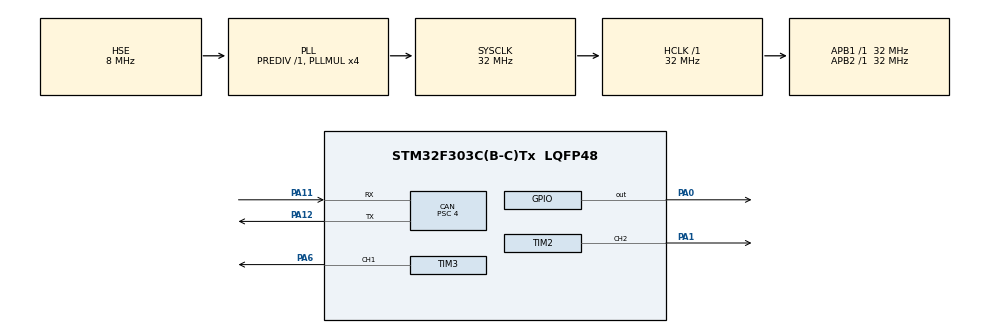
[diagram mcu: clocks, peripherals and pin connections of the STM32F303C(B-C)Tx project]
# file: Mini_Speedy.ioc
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CAN.BS1=CAN_BS1_5TQ
CAN.BS2=CAN_BS2_2TQ
CAN.CalculateBaudRate=1000000
CAN.CalculateTimeBit=1000
CAN.CalculateTimeQuantum=125.0
CAN.Prescaler=4
Mcu.Family=STM32F3
Mcu.Name=STM32F303C(B-C)Tx
Mcu.Package=LQFP48
NVIC.PriorityGroup=NVIC_PRIORITYGROUP_4
PA0.Signal=GPIO_Output
PA1.Signal=S_TIM2_CH2
PA11.Mode=CAN_Activate
PA11.Signal=CAN_RX
PA12.Mode=CAN_Activate
PA12.Signal=CAN_TX
PA6.Signal=S_TIM3_CH1
PF0-OSC_IN.Mode=HSE-External-Oscillator
PF0-OSC_IN.Signal=RCC_OSC_IN
PF1-OSC_OUT.Mode=HSE-External-Oscillator
PF1-OSC_OUT.Signal=RCC_OSC_OUT
ProjectManager.HeapSize=0x200
ProjectManager.StackSize=0x400
ProjectManager.TargetToolchain=STM32CubeIDE
RCC.AHBFreq_Value=32000000
RCC.APB1Freq_Value=32000000
RCC.APB1TimFreq_Value=32000000
RCC.APB2Freq_Value=32000000
RCC.APB2TimFreq_Value=32000000
RCC.CortexFreq_Value=32000000
RCC.HCLKFreq_Value=32000000
RCC.HSE_VALUE=8000000
RCC.HSI_VALUE=8000000
RCC.LSE_VALUE=32768
RCC.PLLMUL=RCC_PLL_MUL4
RCC.PLLSourceVirtual=RCC_PLLSOURCE_HSE
RCC.SYSCLKFreq_VALUE=32000000
RCC.SYSCLKSourceVirtual=RCC_SYSCLKSOURCE_PLLCLK
RCC.USBFreq_Value=32000000
SH.S_TIM2_CH2.0=TIM2_CH2,PWM Generation2 CH2
SH.S_TIM3_CH1.0=TIM3_CH1,PWM Generation1 CH1
TIM2.AutoReloadPreload=TIM_AUTORELOAD_PRELOAD_ENABLE
TIM2.Channel-PWM\ Generation2\ CH2=TIM_CHANNEL_2
TIM2.Period=255
TIM2.Prescaler=6
TIM3.AutoReloadPreload=TIM_AUTORELOAD_PRELOAD_ENABLE
TIM3.Channel-PWM\ Generation1\ CH1=TIM_CHANNEL_1
TIM3.Period=999
TIM3.Prescaler=639
TIM3.Pulse-PWM\ Generation1\ CH1=75
VP_TIM2_VS_ClockSourceINT.Mode=Internal
VP_TIM3_VS_ClockSourceINT.Mode=Internal
board=custom

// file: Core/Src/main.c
/* USER CODE BEGIN Header */
/**
  ******************************************************************************
  * @file           : main.c
  * @brief          : Main program body
  ******************************************************************************
  * @attention
  *
  * Copyright (c) 2024 STMicroelectronics.
  * All rights reserved.
  *
  * This software is licensed under terms that can be found in the LICENSE file
  * in the root directory of this software component.
  * If no LICENSE file comes with this software, it is provided AS-IS.
  *
  ******************************************************************************
  */
/* USER CODE END Header */
#include "main.h"

/* USER CODE BEGIN PD */

// CAN ID of device (4 bits)
#define CAN_ID 0b0001

#define CAN_ID_MASK 		0b00000000000011110000000000000000
#define CAN_ACTUATOR_MASK 	0b00000000000000001111000000000000

// The number of data bytes in the CAN data frames (float32 values).
#define CAN_DATA_SIZE 4

/* USER CODE END PD */

CAN_HandleTypeDef hcan;

TIM_HandleTypeDef htim2;
TIM_HandleTypeDef htim3;

void SystemClock_Config(void);
static void MX_GPIO_Init(void);
static void MX_CAN_Init(void);
static void MX_TIM2_Init(void);
static void MX_TIM3_Init(void);

/* USER CODE BEGIN 0 */
void CAN_Transmit(
    CAN_HandleTypeDef* hcan,
    CAN_TxHeaderTypeDef* CAN_TxHeader,
    uint32_t* CAN_TxMailbox);
// Initializes the CANBus filter for the board.
void CAN_Filter(CAN_HandleTypeDef* hcan, CAN_TxHeaderTypeDef* CAN_TxHeader);

/* USER CODE END 0 */

int main(void)
{

  /* MCU Configuration--------------------------------------------------------*/

  /* Reset of all peripherals, Initializes the Flash interface and the Systick. */
  HAL_Init();

  /* Configure the system clock */
  SystemClock_Config();

  /* Initialize all configured peripherals */
  MX_GPIO_Init();
  MX_CAN_Init();
  MX_TIM2_Init();
  MX_TIM3_Init();
  /* USER CODE BEGIN 2 */
  HAL_TIM_PWM_Start(&htim2, TIM_CHANNEL_2);
  HAL_TIM_PWM_Start(&htim3, TIM_CHANNEL_1);

  CAN_TxHeaderTypeDef CAN_TxHeader; // The transmission header.
  CAN_RxHeaderTypeDef CAN_RxHeader; // The receiver header.
  uint32_t CAN_TxMailbox = 0;
  uint8_t CAN_TxData[CAN_DATA_SIZE] = {};
  uint8_t CAN_RxData[CAN_DATA_SIZE] = {};
  CAN_Filter(&hcan, &CAN_TxHeader); // Initializing the CANbus filter
  HAL_CAN_Start(&hcan);

  int pulse = 0;

  /* USER CODE END 2 */

  /* Infinite loop */
  /* USER CODE BEGIN WHILE */
  while (1)
  {
	  pulse = pulse + 1;
	  if (pulse > 255) {
		  pulse = 0;
	  }
	  //__HAL_TIM_SET_COMPARE(&htim2, TIM_CHANNEL_2, pulse);

	  HAL_Delay(500);

	  if (HAL_CAN_GetRxFifoFillLevel(&hcan, CAN_RX_FIFO0) == 0){
		  continue;
	  }
	  HAL_CAN_GetRxMessage(&hcan, CAN_RX_FIFO0, &CAN_RxHeader, CAN_RxData);
	  uint8_t actuatorID = (uint8_t)((CAN_RxHeader.ExtId & CAN_ACTUATOR_MASK) >> 12);

	  CAN_TxData[0] = (uint8_t)((CAN_RxHeader.ExtId) >> 24);;
	  CAN_TxData[1] = (uint8_t)((CAN_RxHeader.ExtId) >> 16);;
	  CAN_TxData[2] = (uint8_t)((CAN_RxHeader.ExtId) >> 8);;
	  CAN_TxData[3] = (uint8_t)((CAN_RxHeader.ExtId) >> 0);;
	  HAL_CAN_AddTxMessage(&hcan, &CAN_TxHeader, CAN_TxData, &CAN_TxMailbox);

	  switch(actuatorID){
		  case 0b0000:{
			  CAN_TxData[0] = 0b0001;
			  CAN_TxData[1] = 0;
			  CAN_TxData[2] = 0;
			  CAN_TxData[3] = 0;
			  HAL_CAN_AddTxMessage(&hcan, &CAN_TxHeader, CAN_TxData, &CAN_TxMailbox);
		  }
		  case 0b0001:{
			  __HAL_TIM_SET_COMPARE(&htim3, TIM_CHANNEL_1, CAN_RxData[0]);
			  break;
		  }
		  case 0b0010:{
			  break;
		  }
	  }
    /* USER CODE END WHILE */

  }
}

void SystemClock_Config(void)
{
  RCC_OscInitTypeDef RCC_OscInitStruct = {0};
  RCC_ClkInitTypeDef RCC_ClkInitStruct = {0};

  /** Initializes the RCC Oscillators according to the specified parameters
  * in the RCC_OscInitTypeDef structure.
  */
  RCC_OscInitStruct.OscillatorType = RCC_OSCILLATORTYPE_HSE;
  RCC_OscInitStruct.HSEState = RCC_HSE_ON;
  RCC_OscInitStruct.HSEPredivValue = RCC_HSE_PREDIV_DIV1;
  RCC_OscInitStruct.HSIState = RCC_HSI_ON;
  RCC_OscInitStruct.PLL.PLLState = RCC_PLL_ON;
  RCC_OscInitStruct.PLL.PLLSource = RCC_PLLSOURCE_HSE;
  RCC_OscInitStruct.PLL.PLLMUL = RCC_PLL_MUL4;
  if (HAL_RCC_OscConfig(&RCC_OscInitStruct) != HAL_OK)
  {
    Error_Handler();
  }

  /** Initializes the CPU, AHB and APB buses clocks
  */
  RCC_ClkInitStruct.ClockType = RCC_CLOCKTYPE_HCLK|RCC_CLOCKTYPE_SYSCLK
                              |RCC_CLOCKTYPE_PCLK1|RCC_CLOCKTYPE_PCLK2;
  RCC_ClkInitStruct.SYSCLKSource = RCC_SYSCLKSOURCE_PLLCLK;
  RCC_ClkInitStruct.AHBCLKDivider = RCC_SYSCLK_DIV1;
  RCC_ClkInitStruct.APB1CLKDivider = RCC_HCLK_DIV1;
  RCC_ClkInitStruct.APB2CLKDivider = RCC_HCLK_DIV1;

  if (HAL_RCC_ClockConfig(&RCC_ClkInitStruct, FLASH_LATENCY_1) != HAL_OK)
  {
    Error_Handler();
  }
}

static void MX_CAN_Init(void)
{

  hcan.Instance = CAN;
  hcan.Init.Prescaler = 4;
  hcan.Init.Mode = CAN_MODE_NORMAL;
  hcan.Init.SyncJumpWidth = CAN_SJW_1TQ;
  hcan.Init.TimeSeg1 = CAN_BS1_5TQ;
  hcan.Init.TimeSeg2 = CAN_BS2_2TQ;
  hcan.Init.TimeTriggeredMode = DISABLE;
  hcan.Init.AutoBusOff = DISABLE;
  hcan.Init.AutoWakeUp = DISABLE;
  hcan.Init.AutoRetransmission = DISABLE;
  hcan.Init.ReceiveFifoLocked = DISABLE;
  hcan.Init.TransmitFifoPriority = DISABLE;
  if (HAL_CAN_Init(&hcan) != HAL_OK)
  {
    Error_Handler();
  }

}

static void MX_TIM2_Init(void)
{

  TIM_ClockConfigTypeDef sClockSourceConfig = {0};
  TIM_MasterConfigTypeDef sMasterConfig = {0};
  TIM_OC_InitTypeDef sConfigOC = {0};

  htim2.Instance = TIM2;
  htim2.Init.Prescaler = 0;
  htim2.Init.CounterMode = TIM_COUNTERMODE_UP;
  htim2.Init.Period = 255;
  htim2.Init.ClockDivision = TIM_CLOCKDIVISION_DIV1;
  htim2.Init.AutoReloadPreload = TIM_AUTORELOAD_PRELOAD_ENABLE;
  if (HAL_TIM_Base_Init(&htim2) != HAL_OK)
  {
    Error_Handler();
  }
  sClockSourceConfig.ClockSource = TIM_CLOCKSOURCE_INTERNAL;
  if (HAL_TIM_ConfigClockSource(&htim2, &sClockSourceConfig) != HAL_OK)
  {
    Error_Handler();
  }
  if (HAL_TIM_PWM_Init(&htim2) != HAL_OK)
  {
    Error_Handler();
  }
  sMasterConfig.MasterOutputTrigger = TIM_TRGO_RESET;
  sMasterConfig.MasterSlaveMode = TIM_MASTERSLAVEMODE_DISABLE;
  if (HAL_TIMEx_MasterConfigSynchronization(&htim2, &sMasterConfig) != HAL_OK)
  {
    Error_Handler();
  }
  sConfigOC.OCMode = TIM_OCMODE_PWM1;
  sConfigOC.Pulse = 0;
  sConfigOC.OCPolarity = TIM_OCPOLARITY_HIGH;
  sConfigOC.OCFastMode = TIM_OCFAST_DISABLE;
  if (HAL_TIM_PWM_ConfigChannel(&htim2, &sConfigOC, TIM_CHANNEL_2) != HAL_OK)
  {
    Error_Handler();
  }
  HAL_TIM_MspPostInit(&htim2);

}

static void MX_TIM3_Init(void)
{

  TIM_ClockConfigTypeDef sClockSourceConfig = {0};
  TIM_MasterConfigTypeDef sMasterConfig = {0};
  TIM_OC_InitTypeDef sConfigOC = {0};

  htim3.Instance = TIM3;
  htim3.Init.Prescaler = 639;
  htim3.Init.CounterMode = TIM_COUNTERMODE_UP;
  htim3.Init.Period = 999;
  htim3.Init.ClockDivision = TIM_CLOCKDIVISION_DIV1;
  htim3.Init.AutoReloadPreload = TIM_AUTORELOAD_PRELOAD_ENABLE;
  if (HAL_TIM_Base_Init(&htim3) != HAL_OK)
  {
    Error_Handler();
  }
  sClockSourceConfig.ClockSource = TIM_CLOCKSOURCE_INTERNAL;
  if (HAL_TIM_ConfigClockSource(&htim3, &sClockSourceConfig) != HAL_OK)
  {
    Error_Handler();
  }
  if (HAL_TIM_PWM_Init(&htim3) != HAL_OK)
  {
    Error_Handler();
  }
  sMasterConfig.MasterOutputTrigger = TIM_TRGO_RESET;
  sMasterConfig.MasterSlaveMode = TIM_MASTERSLAVEMODE_DISABLE;
  if (HAL_TIMEx_MasterConfigSynchronization(&htim3, &sMasterConfig) != HAL_OK)
  {
    Error_Handler();
  }
  sConfigOC.OCMode = TIM_OCMODE_PWM1;
  sConfigOC.Pulse = 75;
  sConfigOC.OCPolarity = TIM_OCPOLARITY_HIGH;
  sConfigOC.OCFastMode = TIM_OCFAST_DISABLE;
  if (HAL_TIM_PWM_ConfigChannel(&htim3, &sConfigOC, TIM_CHANNEL_1) != HAL_OK)
  {
    Error_Handler();
  }
  HAL_TIM_MspPostInit(&htim3);

}

static void MX_GPIO_Init(void)
{
  GPIO_InitTypeDef GPIO_InitStruct = {0};

  /* GPIO Ports Clock Enable */
  __HAL_RCC_GPIOF_CLK_ENABLE();
  __HAL_RCC_GPIOA_CLK_ENABLE();
  __HAL_RCC_GPIOB_CLK_ENABLE();

  /*Configure GPIO pin Output Level */
  HAL_GPIO_WritePin(GPIOB, GPIO_PIN_9, GPIO_PIN_RESET);

  /*Configure GPIO pin : PB9 */
  GPIO_InitStruct.Pin = GPIO_PIN_9;
  GPIO_InitStruct.Mode = GPIO_MODE_OUTPUT_PP;
  GPIO_InitStruct.Pull = GPIO_NOPULL;
  GPIO_InitStruct.Speed = GPIO_SPEED_FREQ_LOW;
  HAL_GPIO_Init(GPIOB, &GPIO_InitStruct);

}

/* USER CODE BEGIN 4 */
void CAN_Filter(CAN_HandleTypeDef* hcan, CAN_TxHeaderTypeDef* CAN_TxHeader)
{ // This function initializes the CAN filter for the board.
  // The CANID ports are named for their respective address bits, i.e., 0 to the 0th bit.

    // Setting up the TxHeader
    CAN_TxHeader->IDE = CAN_ID_EXT; // Extended identifier, not the standard length.
    CAN_TxHeader->RTR = CAN_RTR_DATA; // Specifying data frames, not remote frames.
    CAN_TxHeader->DLC = CAN_DATA_SIZE; // CAN_SIZE_DATA; //The data size (5 bytes)
    CAN_TxHeader->ExtId = 0; // Needs to be changed depending on the frame

    // Setting the extended transmission header based on the CAN pins

    CAN_TxHeader->ExtId |= (uint32_t)(CAN_ID << 12);

    CAN_FilterTypeDef CAN_FILTER_CONFIG; // Declaring the filter structure.
    CAN_FILTER_CONFIG.FilterFIFOAssignment = CAN_FILTER_FIFO0; // Choosing the FIFO0 set.
    CAN_FILTER_CONFIG.FilterIdHigh = (uint32_t)(CAN_ID >> 1);
    CAN_FILTER_CONFIG.FilterIdLow = (uint32_t)((CAN_ID << 15) & 0xFFFF);
    CAN_FILTER_CONFIG.FilterMaskIdHigh = (uint32_t)(CAN_ID_MASK >> 16);
    CAN_FILTER_CONFIG.FilterMaskIdLow = (uint32_t)(CAN_ID_MASK & 0xFFFF);
    CAN_FILTER_CONFIG.FilterBank = 0;
    CAN_FILTER_CONFIG.FilterMode = CAN_FILTERMODE_IDMASK; // Using the mask mode to ignore certain bits.
    CAN_FILTER_CONFIG.FilterScale = CAN_FILTERSCALE_32BIT; // Using the extended ID so 32bit filters.
    CAN_FILTER_CONFIG.FilterActivation = CAN_FILTER_ENABLE; // Enabling the filter.
    HAL_CAN_ConfigFilter(hcan, &CAN_FILTER_CONFIG);
}
/* USER CODE END 4 */

void Error_Handler(void)
{
  __disable_irq();
  while (1)
  {
  }
}
